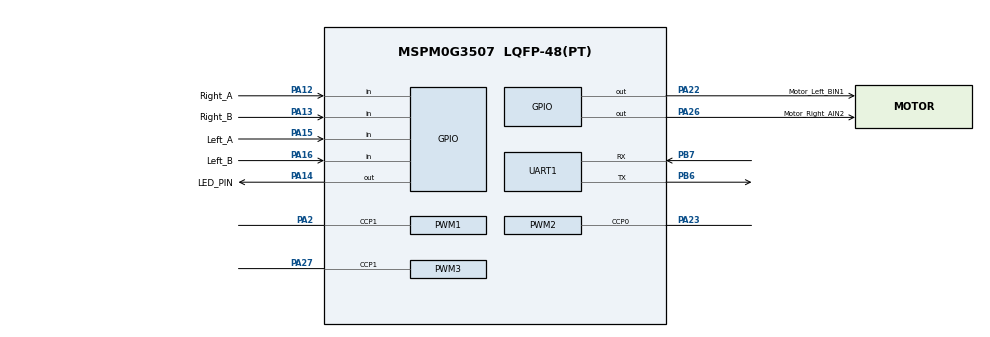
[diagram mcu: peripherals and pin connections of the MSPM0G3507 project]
/**
 * These arguments were used when this file was generated. They will be automatically applied on subsequent loads
 * via the GUI or CLI. Run CLI with '--help' for additional information on how to override these arguments.
 * @cliArgs --device "MSPM0G350X" --part "Default" --package "LQFP-48(PT)" --product "mspm0_sdk@2.10.00.04"
 * @v2CliArgs --device "MSPM0G3507" --package "LQFP-48(PT)" --product "mspm0_sdk@2.10.00.04"
 * @versions {"tool":"1.27.0+4565"}
 */

/**
 * Import the modules used in this configuration.
 */
const Board    = scripting.addModule("/ti/driverlib/Board");
const CAPTURE  = scripting.addModule("/ti/driverlib/CAPTURE", {}, false);
const CAPTURE1 = CAPTURE.addInstance();
const GPIO     = scripting.addModule("/ti/driverlib/GPIO", {}, false);
const GPIO1    = GPIO.addInstance();
const GPIO2    = GPIO.addInstance();
const GPIO3    = GPIO.addInstance();
const GPIO4    = GPIO.addInstance();
const PWM      = scripting.addModule("/ti/driverlib/PWM", {}, false);
const PWM1     = PWM.addInstance();
const PWM2     = PWM.addInstance();
const PWM3     = PWM.addInstance();
const SYSCTL   = scripting.addModule("/ti/driverlib/SYSCTL");
const UART     = scripting.addModule("/ti/driverlib/UART", {}, false);
const UART1    = UART.addInstance();

/**
 * Write custom configuration values to the imported modules.
 */
const divider6       = system.clockTree["PLL_CLK2X_DIV"];
divider6.divideValue = 4;

const divider7       = system.clockTree["PLL_PDIV"];
divider7.divideValue = 2;

const divider9       = system.clockTree["UDIV"];
divider9.divideValue = 2;

const gate7  = system.clockTree["MFCLKGATE"];
gate7.enable = true;

const gate8  = system.clockTree["MFPCLKGATE"];
gate8.enable = true;

const multiplier2         = system.clockTree["PLL_QDIV"];
multiplier2.multiplyValue = 10;

const mux8       = system.clockTree["HSCLKMUX"];
mux8.inputSelect = "HSCLKMUX_SYSPLL2X";


CAPTURE1.$name               = "CAPTURE_ULTRASONIC";
CAPTURE1.timerPeriod         = "50 ms";
CAPTURE1.captMode            = "PULSE_WIDTH_UP";
CAPTURE1.ccIndex             = 1;
CAPTURE1.timerStartTimer     = true;
CAPTURE1.peripheral.$assign  = "TIMG12";
CAPTURE1.ccp1PinConfig.$name = "ti_driverlib_gpio_GPIOPinGeneric0";

GPIO1.$name                         = "LED";
GPIO1.associatedPins[0].$name       = "LED_PIN";
GPIO1.associatedPins[0].pin.$assign = "PA14";

GPIO2.$name                          = "OLED";
GPIO2.associatedPins.create(2);
GPIO2.associatedPins[0].$name        = "SCL";
GPIO2.associatedPins[0].initialValue = "SET";
GPIO2.associatedPins[0].assignedPort = "PORTB";
GPIO2.associatedPins[0].assignedPin  = "2";
GPIO2.associatedPins[1].$name        = "SDA";
GPIO2.associatedPins[1].initialValue = "SET";
GPIO2.associatedPins[1].assignedPort = "PORTB";
GPIO2.associatedPins[1].assignedPin  = "3";

GPIO3.$name                         = "Motor";
GPIO3.port                          = "PORTA";
GPIO3.associatedPins.create(2);
GPIO3.associatedPins[0].$name       = "Motor_Left_BIN1";
GPIO3.associatedPins[0].pin.$assign = "PA22";
GPIO3.associatedPins[1].$name       = "Motor_Right_AIN2";
GPIO3.associatedPins[1].pin.$assign = "PA26";

GPIO4.$name                              = "Encoder";
GPIO4.port                               = "PORTA";
GPIO4.associatedPins.create(4);
GPIO4.associatedPins[0].$name            = "Left_A";
GPIO4.associatedPins[0].direction        = "INPUT";
GPIO4.associatedPins[0].interruptEn      = true;
GPIO4.associatedPins[0].polarity         = "RISE_FALL";
GPIO4.associatedPins[0].internalResistor = "PULL_UP";
GPIO4.associatedPins[0].pin.$assign      = "PA15";
GPIO4.associatedPins[1].$name            = "Left_B";
GPIO4.associatedPins[1].direction        = "INPUT";
GPIO4.associatedPins[1].pin.$assign      = "PA16";
GPIO4.associatedPins[2].$name            = "Right_A";
GPIO4.associatedPins[2].direction        = "INPUT";
GPIO4.associatedPins[2].interruptEn      = true;
GPIO4.associatedPins[2].polarity         = "RISE_FALL";
GPIO4.associatedPins[2].internalResistor = "PULL_UP";
GPIO4.associatedPins[2].pin.$assign      = "PA12";
GPIO4.associatedPins[3].$name            = "Right_B";
GPIO4.associatedPins[3].direction        = "INPUT";
GPIO4.associatedPins[3].pin.$assign      = "PA13";

PWM1.$name                              = "PWM_ULTRASONIC";
PWM1.clockPrescale                      = 250;
PWM1.timerCount                         = 64000;
PWM1.timerStartTimer                    = true;
PWM1.ccIndex                            = [1];
PWM1.ccp1PinConfig.direction            = scripting.forceWrite("OUTPUT");
PWM1.ccp1PinConfig.hideOutputInversion  = scripting.forceWrite(false);
PWM1.ccp1PinConfig.onlyInternalResistor = scripting.forceWrite(false);
PWM1.ccp1PinConfig.passedPeripheralType = scripting.forceWrite("Digital");
PWM1.ccp1PinConfig.$name                = "ti_driverlib_gpio_GPIOPinGeneric1";
PWM1.peripheral.$assignAllowConflicts   = "TIMG8";
PWM1.peripheral.ccp1Pin.$assign         = "PA2";
PWM1.PWM_CHANNEL_1.$name                = "ti_driverlib_pwm_PWMTimerCC0";
PWM1.PWM_CHANNEL_1.dutyCycle            = 50;

PWM2.$name                              = "Motor_Left_BIN2";
PWM2.clockPrescale                      = 250;
PWM2.clockDivider                       = 2;
PWM2.timerCount                         = 64000;
PWM2.ccIndex                            = [0];
PWM2.PWM_CHANNEL_0.$name                = "ti_driverlib_pwm_PWMTimerCC1";
PWM2.PWM_CHANNEL_0.dutyCycle            = 100;
PWM2.ccp0PinConfig.direction            = scripting.forceWrite("OUTPUT");
PWM2.ccp0PinConfig.hideOutputInversion  = scripting.forceWrite(false);
PWM2.ccp0PinConfig.onlyInternalResistor = scripting.forceWrite(false);
PWM2.ccp0PinConfig.passedPeripheralType = scripting.forceWrite("Digital");
PWM2.ccp0PinConfig.$name                = "ti_driverlib_gpio_GPIOPinGeneric4";
PWM2.peripheral.$assignAllowConflicts   = "TIMG8";
PWM2.peripheral.ccp0Pin.$assign         = "PA23";

PWM3.$name                              = "Motor_Right_AIN1";
PWM3.clockDivider                       = 2;
PWM3.clockPrescale                      = 250;
PWM3.timerCount                         = 64000;
PWM3.ccIndex                            = [1];
PWM3.ccp1PinConfig.$name                = "ti_driverlib_gpio_GPIOPinGeneric7";
PWM3.ccp1PinConfig.direction            = scripting.forceWrite("OUTPUT");
PWM3.ccp1PinConfig.hideOutputInversion  = scripting.forceWrite(false);
PWM3.ccp1PinConfig.onlyInternalResistor = scripting.forceWrite(false);
PWM3.ccp1PinConfig.passedPeripheralType = scripting.forceWrite("Digital");
PWM3.peripheral.$assign                 = "TIMG7";
PWM3.peripheral.ccp1Pin.$assign         = "PA27";
PWM3.PWM_CHANNEL_1.$name                = "ti_driverlib_pwm_PWMTimerCC3";

SYSCTL.clockTreeEn = true;

UART1.targetBaudRate                   = 115200;
UART1.$name                            = "BlueTooth";
UART1.enabledDMARXTriggers             = "DL_UART_DMA_INTERRUPT_RX";
UART1.enabledDMATXTriggers             = "DL_UART_DMA_INTERRUPT_TX";
UART1.enableFIFO                       = true;
UART1.rxFifoThreshold                  = "DL_UART_RX_FIFO_LEVEL_ONE_ENTRY";
UART1.enabledInterrupts                = ["DMA_DONE_RX","DMA_DONE_TX"];
UART1.peripheral.$assign               = "UART1";
UART1.peripheral.rxPin.$assign         = "PB7";
UART1.peripheral.txPin.$assign         = "PB6";
UART1.txPinConfig.direction            = scripting.forceWrite("OUTPUT");
UART1.txPinConfig.hideOutputInversion  = scripting.forceWrite(false);
UART1.txPinConfig.onlyInternalResistor = scripting.forceWrite(false);
UART1.txPinConfig.passedPeripheralType = scripting.forceWrite("Digital");
UART1.txPinConfig.$name                = "ti_driverlib_gpio_GPIOPinGeneric2";
UART1.rxPinConfig.hideOutputInversion  = scripting.forceWrite(false);
UART1.rxPinConfig.onlyInternalResistor = scripting.forceWrite(false);
UART1.rxPinConfig.passedPeripheralType = scripting.forceWrite("Digital");
UART1.rxPinConfig.$name                = "ti_driverlib_gpio_GPIOPinGeneric3";
UART1.DMA_CHANNEL_RX.srcLength         = "BYTE";
UART1.DMA_CHANNEL_RX.dstLength         = "BYTE";
UART1.DMA_CHANNEL_RX.$name             = "BlueTooth_RX_DMA_CH";
UART1.DMA_CHANNEL_RX.addressMode       = "f2b";
UART1.DMA_CHANNEL_RX.transferMode      = "FULL_CH_REPEAT_SINGLE";
UART1.DMA_CHANNEL_TX.addressMode       = "b2f";
UART1.DMA_CHANNEL_TX.srcLength         = "BYTE";
UART1.DMA_CHANNEL_TX.dstLength         = "BYTE";
UART1.DMA_CHANNEL_TX.$name             = "BlueTooth_TX_DMA_CH";

/**
 * Pinmux solution for unlocked pins/peripherals. This ensures that minor changes to the automatic solver in a future
 * version of the tool will not impact the pinmux you originally saw.  These lines can be completely deleted in order to
 * re-solve from scratch.
 */
Board.peripheral.$suggestSolution                = "DEBUGSS";
Board.peripheral.swclkPin.$suggestSolution       = "PA20";
Board.peripheral.swdioPin.$suggestSolution       = "PA19";
CAPTURE1.peripheral.ccp1Pin.$suggestSolution     = "PA25";
GPIO2.associatedPins[0].pin.$suggestSolution     = "PB2";
GPIO2.associatedPins[1].pin.$suggestSolution     = "PB3";
UART1.DMA_CHANNEL_RX.peripheral.$suggestSolution = "DMA_CH1";
UART1.DMA_CHANNEL_TX.peripheral.$suggestSolution = "DMA_CH0";
